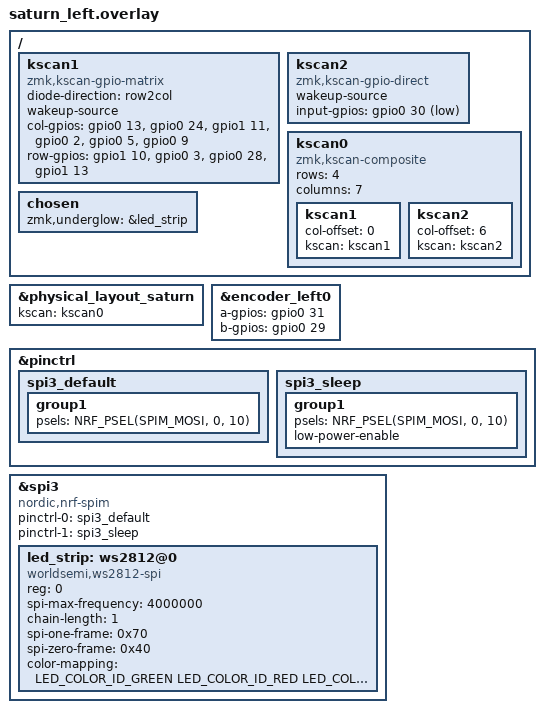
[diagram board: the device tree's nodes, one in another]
/*
 * Copyright (c) 2020 The ZMK Contributors
 *
 * SPDX-License-Identifier: MIT
 */

#include "saturn.dtsi"

// 4x6 matrix
// cols: P0.13 P0.24 P1.11 P0.02 P0.05 P0.09 | rows: P1.10 P0.03 P0.28 P1.13
/ {
    kscan1: kscan1 {
        compatible = "zmk,kscan-gpio-matrix";
        diode-direction = "row2col";
        wakeup-source;

        col-gpios
            = <&gpio0 13 (GPIO_ACTIVE_HIGH | GPIO_PULL_DOWN)>
            , <&gpio0 24 (GPIO_ACTIVE_HIGH | GPIO_PULL_DOWN)>
            , <&gpio1 11 (GPIO_ACTIVE_HIGH | GPIO_PULL_DOWN)>
            , <&gpio0 2 (GPIO_ACTIVE_HIGH | GPIO_PULL_DOWN)>
            , <&gpio0 5 (GPIO_ACTIVE_HIGH | GPIO_PULL_DOWN)>
            , <&gpio0 9 (GPIO_ACTIVE_HIGH | GPIO_PULL_DOWN)>
            ;

        row-gpios
            = <&gpio1 10 GPIO_ACTIVE_HIGH>
            , <&gpio0 3 GPIO_ACTIVE_HIGH>
            , <&gpio0 28 GPIO_ACTIVE_HIGH>
            , <&gpio1 13 GPIO_ACTIVE_HIGH>
            ;
    };
};

// Direct pin (single extra key) on P0.30
/ {
    kscan2: kscan2 {
        compatible = "zmk,kscan-gpio-direct";
        wakeup-source;

        input-gpios
            = <&gpio0 30 (GPIO_ACTIVE_LOW | GPIO_PULL_UP)>
            ;
    };
};

/ {
    kscan0: kscan0 {
        compatible = "zmk,kscan-composite";
        rows = <4>;
        columns = <7>;

        kscan1 {
            col-offset = <0>;
            kscan = <&kscan1>;
        };
        kscan2 {
            col-offset = <6>;
            kscan = <&kscan2>;
        };
    };
};

&physical_layout_saturn {
    kscan = <&kscan0>;
};

// Encoder (real pins on this half): A=P0.31, B=P0.29
&encoder_left0 {
    a-gpios = <&gpio0 31 (GPIO_ACTIVE_HIGH | GPIO_PULL_UP)>;
    b-gpios = <&gpio0 29 (GPIO_ACTIVE_HIGH | GPIO_PULL_UP)>;
    status = "okay";
};

// WS2812 RGB underglow on SPI3 (MOSI on P0.10, confirmed wiring), chain length 1
&pinctrl {
    spi3_default: spi3_default {
        group1 {
            psels = <NRF_PSEL(SPIM_MOSI, 0, 10)>;
        };
    };

    spi3_sleep: spi3_sleep {
        group1 {
            psels = <NRF_PSEL(SPIM_MOSI, 0, 10)>;
            low-power-enable;
        };
    };
};

&spi3 {
    compatible = "nordic,nrf-spim";
    status = "okay";
    pinctrl-0 = <&spi3_default>;
    pinctrl-1 = <&spi3_sleep>;
    pinctrl-names = "default", "sleep";
};

#include <dt-bindings/led/led.h>
&spi3 {
    led_strip: ws2812@0 {
        compatible = "worldsemi,ws2812-spi";
        reg = <0>;
        spi-max-frequency = <4000000>;

        chain-length = <1>;
        spi-one-frame = <0x70>;
        spi-zero-frame = <0x40>;
        color-mapping = <LED_COLOR_ID_GREEN
                         LED_COLOR_ID_RED
                         LED_COLOR_ID_BLUE>;
    };
};

/ {
    chosen {
        zmk,underglow = &led_strip;
    };
};
